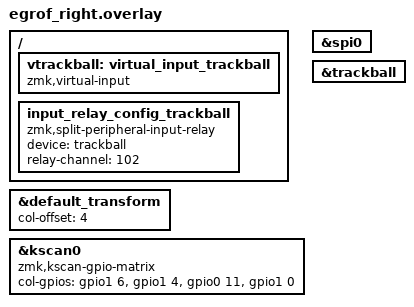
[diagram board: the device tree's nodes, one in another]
#include "egrof.dtsi"
#include "egrof_3610.dtsi"
#include "egrof_nview.dtsi"

&default_transform {
	col-offset = <4>;
};

&kscan0 {
	compatible = "zmk,kscan-gpio-matrix";
	
  col-gpios
      = <&gpio1 6 GPIO_ACTIVE_HIGH>
      , <&gpio1 4 GPIO_ACTIVE_HIGH>
      , <&gpio0 11 GPIO_ACTIVE_HIGH>
      , <&gpio1 0 GPIO_ACTIVE_HIGH>
      ;
};

&spi0 {
    status = "okay";
};

&trackball {
    status = "okay";
};

/ {
	vtrackball: virtual_input_trackball {
		compatible = "zmk,virtual-input";
	};

	input_relay_config_trackball {
		compatible = "zmk,split-peripheral-input-relay";
		device = <&trackball>;
		relay-channel = <102>;
	};
};
